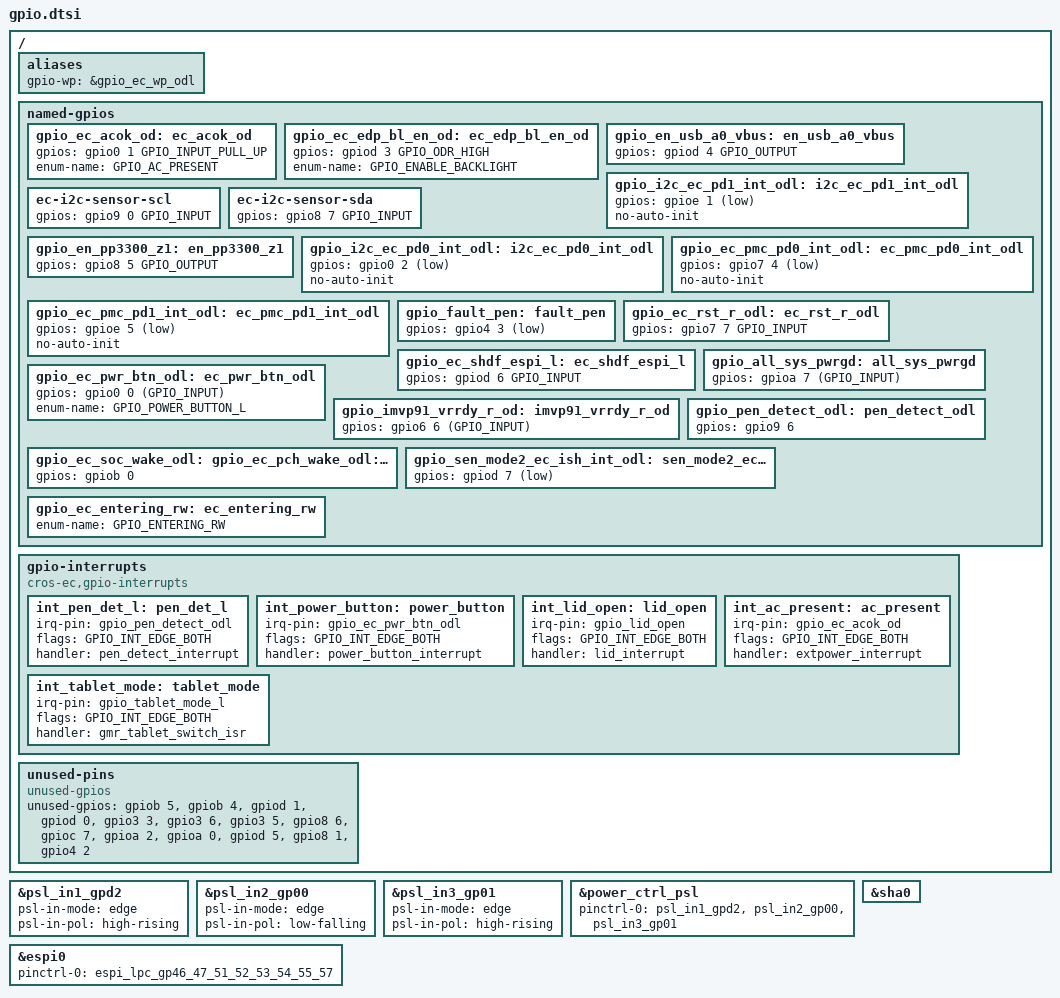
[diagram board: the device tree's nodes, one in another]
/* Copyright 2025 The ChromiumOS Authors
 * Use of this source code is governed by a BSD-style license that can be
 * found in the LICENSE file.
 */

 #include <cros/integrated_fwid.dtsi>

 / {
	aliases {
		gpio-wp = &gpio_ec_wp_odl;
	};

	named-gpios {
		/delete-node/ acok_od;
		/delete-node/ ec_pmc_pd_int_odl;
		/delete-node/ gsc_ec_pwr_btn_odl;
		/delete-node/ ec_tris_l;
		/delete-node/ en_kb_bl;
		/delete-node/ en_z1_rails;
		/delete-node/ imvp91_vrrdy_r_od;
		/delete-node/ vccin_aux_r_vid0;
		/delete-node/ vccin_aux_r_vid1;
		/delete-node/ imu_int_l;
		/delete-node/ i2c_ec_pd_int_odl;
		/delete-node/ en_kb_bl;
		/delete-node/ volup_btn_odl;
		/delete-node/ voldn_btn_odl;
		/delete-node/ ccd_mode_odl;
		/delete-node/ all_sys_pwrgd;
		/delete-node/ ec_pwr_btn_odl;
		/delete-node/ imvp91_vrrdy_r_od;
		/delete-node/ en_pp5000_vbus;

		gpio_ec_acok_od: ec_acok_od {
			gpios = <&gpio0 1 GPIO_INPUT_PULL_UP>;
			enum-name = "GPIO_AC_PRESENT";
		};
		gpio_ec_edp_bl_en_od: ec_edp_bl_en_od {
			gpios = <&gpiod 3 GPIO_ODR_HIGH>;
			enum-name = "GPIO_ENABLE_BACKLIGHT";
		};
		gpio_en_usb_a0_vbus: en_usb_a0_vbus {
			gpios = <&gpiod 4 GPIO_OUTPUT>;
		};
		gpio_i2c_ec_pd1_int_odl: i2c_ec_pd1_int_odl {
			gpios = <&gpioe 1 (GPIO_INPUT | GPIO_ACTIVE_LOW)>;
		};
		ec-i2c-sensor-scl {
			gpios = <&gpio9 0 GPIO_INPUT>;
		};
		ec-i2c-sensor-sda {
			gpios = <&gpio8 7 GPIO_INPUT>;
		};
		gpio_en_pp3300_z1: en_pp3300_z1 {
			gpios = <&gpio8 5 GPIO_OUTPUT>;
		};
		gpio_i2c_ec_pd0_int_odl: i2c_ec_pd0_int_odl {
			gpios = <&gpio0 2 (GPIO_INPUT | GPIO_ACTIVE_LOW)>;
		};
		gpio_ec_pmc_pd0_int_odl: ec_pmc_pd0_int_odl {
			gpios = <&gpio7 4 (GPIO_OUTPUT | GPIO_OPEN_DRAIN | GPIO_ACTIVE_LOW)>;
		};
		gpio_ec_pmc_pd1_int_odl: ec_pmc_pd1_int_odl {
			gpios = <&gpioe 5 (GPIO_OUTPUT | GPIO_OPEN_DRAIN | GPIO_ACTIVE_LOW)>;
		};
		gpio_fault_pen: fault_pen {
			gpios = <&gpio4 3 (GPIO_INPUT | GPIO_ACTIVE_LOW)>;
		};
		gpio_ec_rst_r_odl: ec_rst_r_odl {
			gpios = <&gpio7 7 GPIO_INPUT>;
		};
		gpio_ec_shdf_espi_l: ec_shdf_espi_l {
			gpios = <&gpiod 6 GPIO_INPUT>;
		};
		gpio_all_sys_pwrgd: all_sys_pwrgd {
			gpios = <&gpioa 7 (GPIO_INPUT)>;
		};
		gpio_ec_pwr_btn_odl: ec_pwr_btn_odl {
			gpios = <&gpio0 0 (GPIO_INPUT)>;
			enum-name = "GPIO_POWER_BUTTON_L";
		};
		gpio_imvp91_vrrdy_r_od: imvp91_vrrdy_r_od {
			gpios = <&gpio6 6 (GPIO_INPUT)>;
		};
		gpio_pen_detect_odl: pen_detect_odl {
			gpios = <&gpio9 6 (GPIO_INPUT | GPIO_PULL_UP)>;
		};
		gpio_ec_soc_wake_odl: ec_soc_wake_odl {
			gpios = <&gpiob 0 (GPIO_OUTPUT | GPIO_OPEN_DRAIN | GPIO_OUTPUT_INIT_LOW)>;
		};
		gpio_sen_mode2_ec_ish_int_odl: sen_mode2_ec_ish_int_odl {
			gpios = <&gpiod 7 (GPIO_INPUT | GPIO_OPEN_DRAIN | GPIO_ACTIVE_LOW)>;
		};
		/* The legacy system code requires GPIO_ENTERING_RW symbol */
		gpio_ec_entering_rw: ec_entering_rw {
			enum-name = "GPIO_ENTERING_RW";
		};
	};

	gpio-interrupts {
		compatible = "cros-ec,gpio-interrupts";
		int_pen_det_l: pen_det_l {
			irq-pin = <&gpio_pen_detect_odl>;
			flags = <GPIO_INT_EDGE_BOTH>;
			handler = "pen_detect_interrupt";
		};
		int_power_button: power_button {
			irq-pin = <&gpio_ec_pwr_btn_odl>;
			flags = <GPIO_INT_EDGE_BOTH>;
			handler = "power_button_interrupt";
		};
		int_lid_open: lid_open {
			irq-pin = <&gpio_lid_open>;
			flags = <GPIO_INT_EDGE_BOTH>;
			handler = "lid_interrupt";
		};
		int_ac_present: ac_present {
			irq-pin = <&gpio_ec_acok_od>;
			flags = <GPIO_INT_EDGE_BOTH>;
			handler = "extpower_interrupt";
		};
		int_tablet_mode: tablet_mode {
			irq-pin = <&gpio_tablet_mode_l>;
			flags = <GPIO_INT_EDGE_BOTH>;
			handler = "gmr_tablet_switch_isr";
		};
	};
	unused-pins {
		compatible = "unused-gpios";
		unused-gpios =
			<&gpiob 5 0>,
			<&gpiob 4 0>,
			<&gpiod 1 0>,
			<&gpiod 0 0>,
			<&gpio3 3 0>,
			<&gpio3 6 0>,
			<&gpio3 5 0>,
			<&gpio8 6 0>,
			<&gpioc 7 0>,
			<&gpioa 2 0>,
			<&gpioa 0 0>,
			<&gpiod 5 0>,
			<&gpio8 1 0>,
			<&gpio4 2 0>;
	};
};

/* These GPIOS are initialized by the PDC driver */
&gpio_i2c_ec_pd0_int_odl {
	no-auto-init;
};
&gpio_i2c_ec_pd1_int_odl {
	no-auto-init;
};
&gpio_ec_pmc_pd0_int_odl {
	no-auto-init;
};
&gpio_ec_pmc_pd1_int_odl {
	no-auto-init;
};

/* Power switch logic input pads */
/* LID_OPEN_OD */
&psl_in1_gpd2 {
	psl-in-mode = "edge";
	psl-in-pol = "high-rising";
};

/* EC_PWR_BTN_ODL */
&psl_in2_gp00 {
	psl-in-mode = "edge";
	psl-in-pol = "low-falling";
};

/* ACOK_EC_OD */
&psl_in3_gp01 {
	psl-in-mode = "edge";
	psl-in-pol = "high-rising";
};

/* Power domain device controlled by PSL (Power Switch Logic) IO pads */
&power_ctrl_psl {
	status = "okay";
	pinctrl-names = "sleep";
	pinctrl-0 = <&psl_in1_gpd2 &psl_in2_gp00 &psl_in3_gp01>;
};

/* The eSPI shim requires this GPIO nodelabel */
gpio_ec_pch_wake_odl: &gpio_ec_soc_wake_odl {
};

/* host interface */
&espi0 {
	status = "okay";
	pinctrl-0 = <&espi_lpc_gp46_47_51_52_53_54_55_57>;
	pinctrl-names = "default";
};

&sha0 {
	status = "okay";
};
